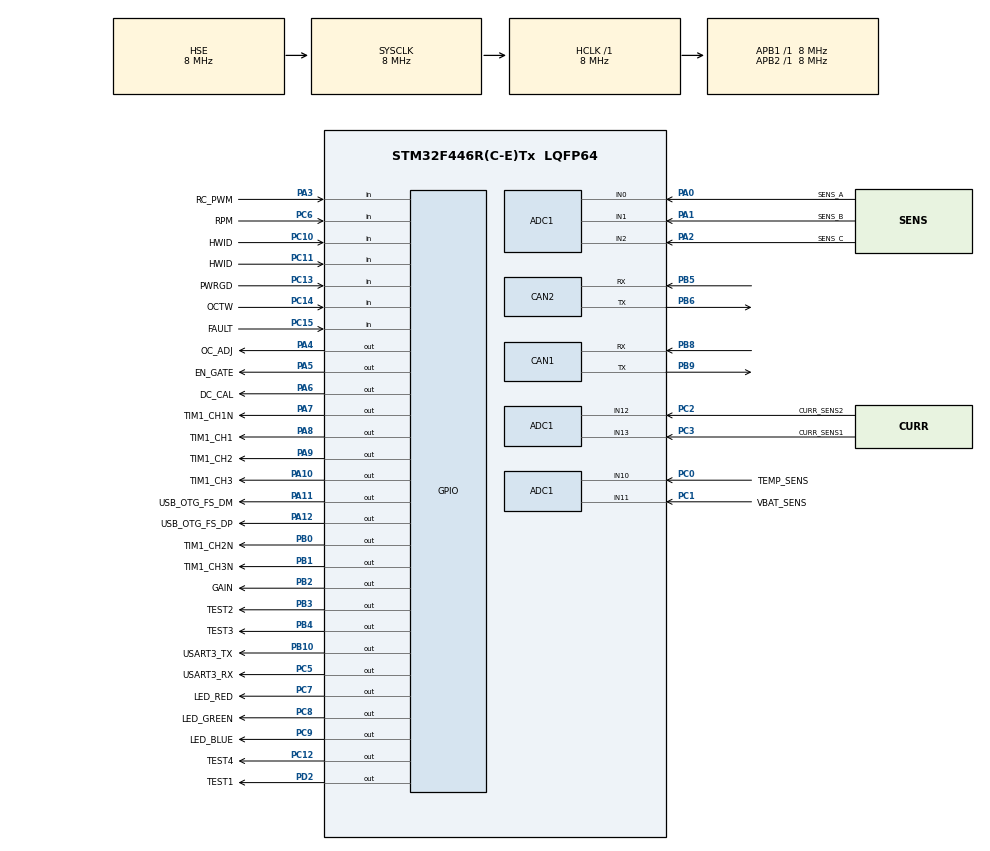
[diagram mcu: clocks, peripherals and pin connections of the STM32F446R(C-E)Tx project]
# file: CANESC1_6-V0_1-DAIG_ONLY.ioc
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ADC1.Channel-0\#ChannelRegularConversion=ADC_CHANNEL_10
ADC1.NbrOfConversionFlag=1
ADC1.Rank-0\#ChannelRegularConversion=1
ADC1.SamplingTime-0\#ChannelRegularConversion=ADC_SAMPLETIME_3CYCLES
ADC1.master=1
CAN1.CalculateTimeBit=6000
CAN1.CalculateTimeQuantum=2000.0
CAN2.CalculateTimeBit=6000
CAN2.CalculateTimeQuantum=2000.0
Mcu.Family=STM32F4
Mcu.Name=STM32F446R(C-E)Tx
Mcu.Package=LQFP64
NVIC.PriorityGroup=NVIC_PRIORITYGROUP_4
PA0-WKUP.GPIO_Label=SENS_A
PA0-WKUP.Signal=ADCx_IN0
PA1.GPIO_Label=SENS_B
PA1.Signal=ADCx_IN1
PA10.GPIO_Label=TIM1_CH3
PA10.Signal=GPIO_Output
PA11.GPIO_Label=USB_OTG_FS_DM
PA11.Signal=GPIO_Output
PA12.GPIO_Label=USB_OTG_FS_DP
PA12.Signal=GPIO_Output
PA13.Mode=Serial-Wire
PA13.Signal=SYS_JTMS-SWDIO
PA14.Mode=Serial-Wire
PA14.Signal=SYS_JTCK-SWCLK
PA15.Signal=SYS_JTDI
PA2.GPIO_Label=SENS_C
PA2.Signal=ADCx_IN2
PA3.GPIO_Label=RC_PWM
PA3.GPIO_Mode=GPIO_MODE_INPUT
PA3.GPIO_PuPd=GPIO_NOPULL
PA3.Signal=GPIO_Input
PA4.GPIO_Label=OC_ADJ
PA4.GPIO_ModeDefaultOutputPP=GPIO_MODE_OUTPUT_PP
PA4.GPIO_PuPd=GPIO_NOPULL
PA4.GPIO_Speed=GPIO_SPEED_LOW
PA4.Signal=GPIO_Output
PA5.GPIO_Label=EN_GATE
PA5.GPIO_ModeDefaultOutputPP=GPIO_MODE_OUTPUT_PP
PA5.GPIO_PuPd=GPIO_NOPULL
PA5.GPIO_Speed=GPIO_SPEED_LOW
PA5.Signal=GPIO_Output
PA6.GPIO_Label=DC_CAL
PA6.GPIO_ModeDefaultOutputPP=GPIO_MODE_OUTPUT_PP
PA6.GPIO_PuPd=GPIO_NOPULL
PA6.GPIO_Speed=GPIO_SPEED_LOW
PA6.Signal=GPIO_Output
PA7.GPIO_Label=TIM1_CH1N
PA7.Signal=GPIO_Output
PA8.GPIO_Label=TIM1_CH1
PA8.Signal=GPIO_Output
PA9.GPIO_Label=TIM1_CH2
PA9.Signal=GPIO_Output
PB0.GPIO_Label=TIM1_CH2N
PB0.Signal=GPIO_Output
PB1.GPIO_Label=TIM1_CH3N
PB1.Signal=GPIO_Output
PB10.GPIO_Label=USART3_TX
PB10.Signal=GPIO_Output
PB2.GPIO_Label=GAIN
PB2.Signal=GPIO_Output
PB3.GPIO_Label=TEST2
PB3.GPIO_ModeDefaultOutputPP=GPIO_MODE_OUTPUT_PP
PB3.GPIO_PuPd=GPIO_NOPULL
PB3.GPIO_Speed=GPIO_SPEED_LOW
PB3.Signal=GPIO_Output
PB4.GPIO_Label=TEST3
PB4.GPIO_ModeDefaultOutputPP=GPIO_MODE_OUTPUT_PP
PB4.GPIO_PuPd=GPIO_NOPULL
PB4.GPIO_Speed=GPIO_SPEED_LOW
PB4.Signal=GPIO_Output
PB5.Mode=Slave
PB5.Signal=CAN2_RX
PB6.Mode=Slave
PB6.Signal=CAN2_TX
PB8.Mode=Master
PB8.Signal=CAN1_RX
PB9.Mode=Master
PB9.Signal=CAN1_TX
PC0.GPIO_Label=TEMP_SENS
PC0.GPIO_Mode=GPIO_MODE_ANALOG
PC0.GPIO_PuPd=GPIO_NOPULL
PC0.Signal=ADCx_IN10
PC1.GPIO_Label=VBAT_SENS
PC1.GPIO_Mode=GPIO_MODE_ANALOG
PC1.GPIO_PuPd=GPIO_NOPULL
PC1.Signal=ADCx_IN11
PC10.GPIO_Label=HWID
PC10.GPIO_Mode=GPIO_MODE_INPUT
PC10.GPIO_PuPd=GPIO_NOPULL
PC10.Signal=GPIO_Input
PC11.GPIO_Label=HWID
PC11.GPIO_Mode=GPIO_MODE_INPUT
PC11.GPIO_PuPd=GPIO_NOPULL
PC11.Signal=GPIO_Input
PC12.GPIO_Label=TEST4
PC12.GPIO_ModeDefaultOutputPP=GPIO_MODE_OUTPUT_PP
PC12.GPIO_PuPd=GPIO_NOPULL
PC12.GPIO_Speed=GPIO_SPEED_LOW
PC12.Signal=GPIO_Output
PC13.GPIO_Label=PWRGD
PC13.Signal=GPIO_Input
PC14-OSC32_IN.GPIO_Label=OCTW
PC14-OSC32_IN.GPIO_Mode=GPIO_MODE_INPUT
PC14-OSC32_IN.GPIO_PuPd=GPIO_NOPULL
PC14-OSC32_IN.Signal=GPIO_Input
PC15-OSC32_OUT.GPIO_Label=FAULT
PC15-OSC32_OUT.GPIO_Mode=GPIO_MODE_INPUT
PC15-OSC32_OUT.GPIO_PuPd=GPIO_NOPULL
PC15-OSC32_OUT.Signal=GPIO_Input
PC2.GPIO_Label=CURR_SENS2
PC2.GPIO_Mode=GPIO_MODE_ANALOG
PC2.GPIO_PuPd=GPIO_NOPULL
PC2.Signal=ADCx_IN12
PC3.GPIO_Label=CURR_SENS1
PC3.GPIO_Mode=GPIO_MODE_ANALOG
PC3.GPIO_PuPd=GPIO_NOPULL
PC3.Signal=ADCx_IN13
PC5.GPIO_Label=USART3_RX
PC5.Signal=GPIO_Output
PC6.GPIO_Label=RPM
PC6.GPIO_Mode=GPIO_MODE_INPUT
PC6.GPIO_PuPd=GPIO_NOPULL
PC6.Signal=GPIO_Input
PC7.GPIO_Label=LED_RED
PC7.GPIO_ModeDefaultOutputPP=GPIO_MODE_OUTPUT_PP
PC7.GPIO_PuPd=GPIO_NOPULL
PC7.GPIO_Speed=GPIO_SPEED_LOW
PC7.Signal=GPIO_Output
PC8.GPIO_Label=LED_GREEN
PC8.GPIO_ModeDefaultOutputPP=GPIO_MODE_OUTPUT_PP
PC8.GPIO_PuPd=GPIO_NOPULL
PC8.GPIO_Speed=GPIO_SPEED_LOW
PC8.Signal=GPIO_Output
PC9.GPIO_Label=LED_BLUE
PC9.GPIO_ModeDefaultOutputPP=GPIO_MODE_OUTPUT_PP
PC9.GPIO_PuPd=GPIO_NOPULL
PC9.GPIO_Speed=GPIO_SPEED_LOW
PC9.Signal=GPIO_Output
PD2.GPIO_Label=TEST1
PD2.GPIO_ModeDefaultOutputPP=GPIO_MODE_OUTPUT_PP
PD2.GPIO_PuPd=GPIO_NOPULL
PD2.GPIO_Speed=GPIO_SPEED_LOW
PD2.Signal=GPIO_Output
PH0-OSC_IN.Mode=HSE-External-Oscillator
PH0-OSC_IN.Signal=RCC_OSC_IN
PH1-OSC_OUT.Mode=HSE-External-Oscillator
PH1-OSC_OUT.Signal=RCC_OSC_OUT
ProjectManager.TargetToolchain=EWARM
RCC.AHBFreq_Value=8000000
RCC.APB1Freq_Value=8000000
RCC.APB1TimFreq_Value=8000000
RCC.APB2Freq_Value=8000000
RCC.APB2TimFreq_Value=8000000
RCC.CortexFreq_Value=8000000
RCC.HCLKFreq_Value=8000000
RCC.HSE_VALUE=8000000
RCC.PLLSourceVirtual=RCC_PLLSOURCE_HSE
RCC.SYSCLKFreq_VALUE=8000000
RCC.SYSCLKSource=RCC_SYSCLKSOURCE_HSE
RCC.USBFreq_Value=48000000
RCC.VCOOutputFreq_Value=96000000
SH.ADCx_IN0.0=ADC1_IN0,IN0
SH.ADCx_IN1.0=ADC1_IN1,IN1
SH.ADCx_IN10.0=ADC1_IN10,IN10
SH.ADCx_IN11.0=ADC1_IN11,IN11
SH.ADCx_IN12.0=ADC1_IN12,IN12
SH.ADCx_IN13.0=ADC1_IN13,IN13
SH.ADCx_IN2.0=ADC1_IN2,IN2

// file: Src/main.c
/**
  ******************************************************************************
  * File Name          : main.c
  * Description        : Main program body
  ******************************************************************************
  *
  * COPYRIGHT(c) 2015 STMicroelectronics
  *
  * Redistribution and use in source and binary forms, with or without modification,
  * are permitted provided that the following conditions are met:
  *   1. Redistributions of source code must retain the above copyright notice,
  *      this list of conditions and the following disclaimer.
  *   2. Redistributions in binary form must reproduce the above copyright notice,
  *      this list of conditions and the following disclaimer in the documentation
  *      and/or other materials provided with the distribution.
  *   3. Neither the name of STMicroelectronics nor the names of its contributors
  *      may be used to endorse or promote products derived from this software
  *      without specific prior written permission.
  *
  * THIS SOFTWARE IS PROVIDED BY THE COPYRIGHT HOLDERS AND CONTRIBUTORS "AS IS"
  * AND ANY EXPRESS OR IMPLIED WARRANTIES, INCLUDING, BUT NOT LIMITED TO, THE
  * IMPLIED WARRANTIES OF MERCHANTABILITY AND FITNESS FOR A PARTICULAR PURPOSE ARE
  * DISCLAIMED. IN NO EVENT SHALL THE COPYRIGHT HOLDER OR CONTRIBUTORS BE LIABLE
  * FOR ANY DIRECT, INDIRECT, INCIDENTAL, SPECIAL, EXEMPLARY, OR CONSEQUENTIAL
  * DAMAGES (INCLUDING, BUT NOT LIMITED TO, PROCUREMENT OF SUBSTITUTE GOODS OR
  * SERVICES; LOSS OF USE, DATA, OR PROFITS; OR BUSINESS INTERRUPTION) HOWEVER
  * CAUSED AND ON ANY THEORY OF LIABILITY, WHETHER IN CONTRACT, STRICT LIABILITY,
  * OR TORT (INCLUDING NEGLIGENCE OR OTHERWISE) ARISING IN ANY WAY OUT OF THE USE
  * OF THIS SOFTWARE, EVEN IF ADVISED OF THE POSSIBILITY OF SUCH DAMAGE.
  *
  ******************************************************************************
  */

#include "stm32f4xx_hal.h"

ADC_HandleTypeDef hadc1;

CAN_HandleTypeDef hcan1;
CAN_HandleTypeDef hcan2;

void SystemClock_Config(void);
static void MX_GPIO_Init(void);
static void MX_ADC1_Init(void);
static void MX_CAN1_Init(void);
static void MX_CAN2_Init(void);

int main(void)
{

  /* MCU Configuration----------------------------------------------------------*/

  /* Reset of all peripherals, Initializes the Flash interface and the Systick. */
  HAL_Init();

  /* Configure the system clock */
  SystemClock_Config();

  /* Initialize all configured peripherals */
  MX_GPIO_Init();
  MX_ADC1_Init();
  MX_CAN1_Init();
  MX_CAN2_Init();

  /* Infinite loop */
  /* USER CODE BEGIN WHILE */

  /*

   [6/11/2015 10:19:57 AM] Pavel Kirienko:
  A comprehensive check of the ADC inputs actually requires a lot of coding
  (so much coding actually, I consider it unfeasible), so I suggest to drop
  this test on the assumption that ADC inputs work. The power stage can be
  checked simply by means of triggering the FETs while keeping an eye on the
  current consumption, so that if there's a short circuit it will be noticed
  (e.g. power the board from a current-limited power supply).

  The algorithm is quite simple:

  - Set all TIM1_CH* outputs to LOW.
  - For each [TIM1_CH1, TIM1_CH2, TIM1_CH3, TIM1_CH1N, TIM1_CH2N, TIM1_CH3N]:
  - Set the output HIGH
  - Wait 100 milliseconds
  - Set the output LOW again

  ftp://pkir.net/CANESC1.6Draft.csv
  [6/11/2015 10:20:20 AM] Pavel Kirienko: Remove the speed column and diff it with the original doc to see the changes
  */
  while (1)
  {
    test();

  /* USER CODE END WHILE */

  }

}

/** System Clock Configuration
*/
void SystemClock_Config(void)
{

  RCC_OscInitTypeDef RCC_OscInitStruct;
  RCC_ClkInitTypeDef RCC_ClkInitStruct;

  __PWR_CLK_ENABLE();

  __HAL_PWR_VOLTAGESCALING_CONFIG(PWR_REGULATOR_VOLTAGE_SCALE3);

  RCC_OscInitStruct.OscillatorType = RCC_OSCILLATORTYPE_HSE;
  RCC_OscInitStruct.HSEState = RCC_HSE_ON;
  RCC_OscInitStruct.PLL.PLLState = RCC_PLL_NONE;
  HAL_RCC_OscConfig(&RCC_OscInitStruct);

  RCC_ClkInitStruct.ClockType = RCC_CLOCKTYPE_SYSCLK;
  RCC_ClkInitStruct.SYSCLKSource = RCC_SYSCLKSOURCE_HSE;
  RCC_ClkInitStruct.AHBCLKDivider = RCC_SYSCLK_DIV1;
  RCC_ClkInitStruct.APB1CLKDivider = RCC_HCLK_DIV1;
  RCC_ClkInitStruct.APB2CLKDivider = RCC_HCLK_DIV1;
  HAL_RCC_ClockConfig(&RCC_ClkInitStruct, FLASH_LATENCY_0);

  HAL_SYSTICK_Config(HAL_RCC_GetHCLKFreq()/1000);

  HAL_SYSTICK_CLKSourceConfig(SYSTICK_CLKSOURCE_HCLK);

}

/* ADC1 init function */
void MX_ADC1_Init(void)
{

  ADC_ChannelConfTypeDef sConfig;

    /**Configure the global features of the ADC (Clock, Resolution, Data Alignment and number of conversion)
    */
  hadc1.Instance = ADC1;
  hadc1.Init.ClockPrescaler = ADC_CLOCKPRESCALER_PCLK_DIV2;
  hadc1.Init.Resolution = ADC_RESOLUTION12b;
  hadc1.Init.ScanConvMode = DISABLE;
  hadc1.Init.ContinuousConvMode = DISABLE;
  hadc1.Init.DiscontinuousConvMode = DISABLE;
  hadc1.Init.ExternalTrigConvEdge = ADC_EXTERNALTRIGCONVEDGE_NONE;
  hadc1.Init.DataAlign = ADC_DATAALIGN_RIGHT;
  hadc1.Init.NbrOfConversion = 1;
  hadc1.Init.DMAContinuousRequests = DISABLE;
  hadc1.Init.EOCSelection = EOC_SINGLE_CONV;
  HAL_ADC_Init(&hadc1);

    /**Configure for the selected ADC regular channel its corresponding rank in the sequencer and its sample time.
    */
  sConfig.Channel = ADC_CHANNEL_10;
  sConfig.Rank = 1;
  sConfig.SamplingTime = ADC_SAMPLETIME_3CYCLES;
  HAL_ADC_ConfigChannel(&hadc1, &sConfig);

}

/* CAN1 init function */
void MX_CAN1_Init(void)
{

  hcan1.Instance = CAN1;
  hcan1.Init.Prescaler = 16;
  hcan1.Init.Mode = CAN_MODE_NORMAL;
  hcan1.Init.SJW = CAN_SJW_1TQ;
  hcan1.Init.BS1 = CAN_BS1_1TQ;
  hcan1.Init.BS2 = CAN_BS2_1TQ;
  hcan1.Init.TTCM = DISABLE;
  hcan1.Init.ABOM = DISABLE;
  hcan1.Init.AWUM = DISABLE;
  hcan1.Init.NART = DISABLE;
  hcan1.Init.RFLM = DISABLE;
  hcan1.Init.TXFP = DISABLE;
  HAL_CAN_Init(&hcan1);

}

/* CAN2 init function */
void MX_CAN2_Init(void)
{

  hcan2.Instance = CAN2;
  hcan2.Init.Prescaler = 16;
  hcan2.Init.Mode = CAN_MODE_NORMAL;
  hcan2.Init.SJW = CAN_SJW_1TQ;
  hcan2.Init.BS1 = CAN_BS1_1TQ;
  hcan2.Init.BS2 = CAN_BS2_1TQ;
  hcan2.Init.TTCM = DISABLE;
  hcan2.Init.ABOM = DISABLE;
  hcan2.Init.AWUM = DISABLE;
  hcan2.Init.NART = DISABLE;
  hcan2.Init.RFLM = DISABLE;
  hcan2.Init.TXFP = DISABLE;
  HAL_CAN_Init(&hcan2);

}

/** Configure pins as
        * Analog
        * Input
        * Output
        * EVENT_OUT
        * EXTI
*/
void MX_GPIO_Init(void)
{

  GPIO_InitTypeDef GPIO_InitStruct;

  /* GPIO Ports Clock Enable */
  __GPIOC_CLK_ENABLE();
  __GPIOH_CLK_ENABLE();
  __GPIOA_CLK_ENABLE();
  __GPIOB_CLK_ENABLE();
  __GPIOD_CLK_ENABLE();

  /*Configure GPIO pins : PC13 PC14 PC15 PC6
                           PC10 PC11 */
  GPIO_InitStruct.Pin = GPIO_PIN_13|GPIO_PIN_14|GPIO_PIN_15|GPIO_PIN_6
                          |GPIO_PIN_10|GPIO_PIN_11;
  GPIO_InitStruct.Mode = GPIO_MODE_INPUT;
  GPIO_InitStruct.Pull = GPIO_NOPULL;
  HAL_GPIO_Init(GPIOC, &GPIO_InitStruct);

  /*Configure GPIO pin : PA3 */
  GPIO_InitStruct.Pin = GPIO_PIN_3;
  GPIO_InitStruct.Mode = GPIO_MODE_INPUT;
  GPIO_InitStruct.Pull = GPIO_NOPULL;
  HAL_GPIO_Init(GPIOA, &GPIO_InitStruct);

  /*Configure GPIO pins : PA4 PA5 PA6 PA7
                           PA8 PA9 PA10 PA11
                           PA12 */
  GPIO_InitStruct.Pin = GPIO_PIN_4|GPIO_PIN_5|GPIO_PIN_6|GPIO_PIN_7
                          |GPIO_PIN_8|GPIO_PIN_9|GPIO_PIN_10|GPIO_PIN_11
                          |GPIO_PIN_12;
  GPIO_InitStruct.Mode = GPIO_MODE_OUTPUT_PP;
  GPIO_InitStruct.Pull = GPIO_NOPULL;
  GPIO_InitStruct.Speed = GPIO_SPEED_LOW;
  HAL_GPIO_Init(GPIOA, &GPIO_InitStruct);

  /*Configure GPIO pins : PC5 PC7 PC8 PC9
                           PC12 */
  GPIO_InitStruct.Pin = GPIO_PIN_5|GPIO_PIN_7|GPIO_PIN_8|GPIO_PIN_9
                          |GPIO_PIN_12;
  GPIO_InitStruct.Mode = GPIO_MODE_OUTPUT_PP;
  GPIO_InitStruct.Pull = GPIO_NOPULL;
  GPIO_InitStruct.Speed = GPIO_SPEED_LOW;
  HAL_GPIO_Init(GPIOC, &GPIO_InitStruct);

  /*Configure GPIO pins : PB0 PB1 PB2 PB10
                           PB3 PB4 */
  GPIO_InitStruct.Pin = GPIO_PIN_0|GPIO_PIN_1|GPIO_PIN_2|GPIO_PIN_10
                          |GPIO_PIN_3|GPIO_PIN_4;
  GPIO_InitStruct.Mode = GPIO_MODE_OUTPUT_PP;
  GPIO_InitStruct.Pull = GPIO_NOPULL;
  GPIO_InitStruct.Speed = GPIO_SPEED_LOW;
  HAL_GPIO_Init(GPIOB, &GPIO_InitStruct);

  /*Configure GPIO pin : PD2 */
  GPIO_InitStruct.Pin = GPIO_PIN_2;
  GPIO_InitStruct.Mode = GPIO_MODE_OUTPUT_PP;
  GPIO_InitStruct.Pull = GPIO_NOPULL;
  GPIO_InitStruct.Speed = GPIO_SPEED_LOW;
  HAL_GPIO_Init(GPIOD, &GPIO_InitStruct);

}

/************************ (C) COPYRIGHT STMicroelectronics *****END OF FILE****/
